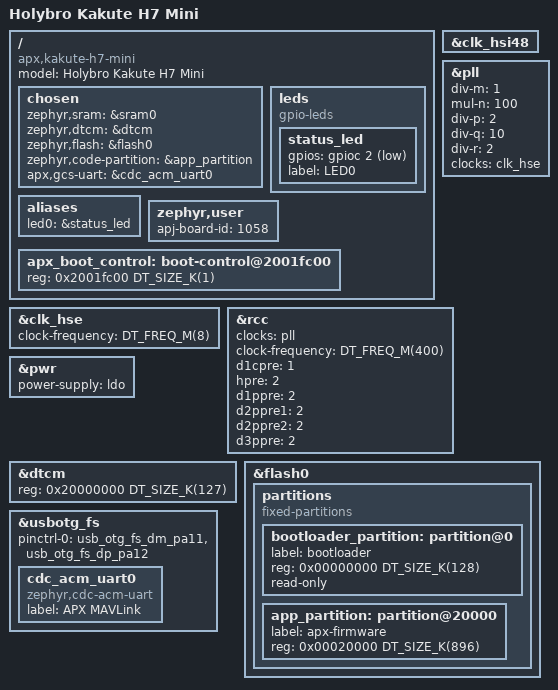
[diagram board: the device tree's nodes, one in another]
/*
 * SPDX-License-Identifier: CC-BY-NC-4.0
 * Copyright (c) 2026 Savita Pawar <savitapawar0402@gmail.com>
 * Author: Savita Pawar (SVPR94)
 * Created: 2026
 *
 * Holybro Kakute H7 Mini (STM32H743xx).
 * Generated by tools/import_board.py from the board's hardware description; re-run it rather than editing.
 */
/dts-v1/;
#include <st/h7/stm32h743Xi.dtsi>
#include <st/h7/stm32h743xihx-pinctrl.dtsi>
#include <zephyr/dt-bindings/gpio/gpio.h>

/ {
	model = "Holybro Kakute H7 Mini";
	compatible = "apx,kakute-h7-mini";

	chosen {
		zephyr,sram = &sram0;
		zephyr,dtcm = &dtcm;
		zephyr,flash = &flash0;
		zephyr,code-partition = &app_partition;
		apx,gcs-uart = &cdc_acm_uart0;
	};

	leds {
		compatible = "gpio-leds";
		status_led: status_led {
			gpios = <&gpioc 2 GPIO_ACTIVE_LOW>;
			label = "LED0";
		};
	};

	aliases {
		led0 = &status_led;
	};

	/* APX board properties - see platforms/zephyr/app/src/board_zephyr.cpp */
	zephyr,user {
		apj-board-id = <1058>;
	};

	/* APX boot control (bootloader <-> firmware handshake), outside every
	 * image's RAM: the last 1 KB of dtcm. */
	apx_boot_control: boot-control@2001fc00 {
		reg = <0x2001fc00 DT_SIZE_K(1)>;
	};
};

&clk_hse {
	clock-frequency = <DT_FREQ_M(8)>;
	status = "okay";
};

/* USB 48 MHz */
&clk_hsi48 {
	status = "okay";
};

/* 8 MHz / 1 = 8 MHz PLL input, * 100 = 800 MHz VCO, / 2 = 400 MHz SYSCLK (VOS1) */
&pll {
	div-m = <1>;
	mul-n = <100>;
	div-p = <2>;
	div-q = <10>;
	div-r = <2>;
	clocks = <&clk_hse>;
	status = "okay";
};

&rcc {
	clocks = <&pll>;
	clock-frequency = <DT_FREQ_M(400)>;
	d1cpre = <1>;
	hpre = <2>;
	d1ppre = <2>;
	d2ppre1 = <2>;
	d2ppre2 = <2>;
	d3ppre = <2>;
};

&pwr {
	power-supply = "ldo";
};

&dtcm {
	reg = <0x20000000 DT_SIZE_K(127)>;
};

&flash0 {
	partitions {
		compatible = "fixed-partitions";
		#address-cells = <1>;
		#size-cells = <1>;

		bootloader_partition: partition@0 {
			label = "bootloader";
			reg = <0x00000000 DT_SIZE_K(128)>;
			read-only;
		};
		app_partition: partition@20000 {
			label = "apx-firmware";
			reg = <0x00020000 DT_SIZE_K(896)>;
		};
	};
};

zephyr_udc0: &usbotg_fs {
	pinctrl-0 = <&usb_otg_fs_dm_pa11 &usb_otg_fs_dp_pa12>;
	pinctrl-names = "default";
	status = "okay";

	cdc_acm_uart0: cdc_acm_uart0 {
		compatible = "zephyr,cdc-acm-uart";
		label = "APX MAVLink";
	};
};
